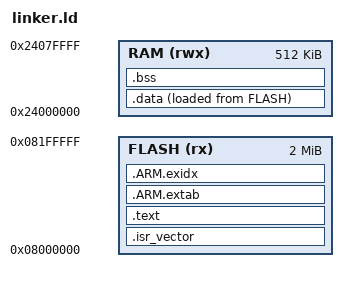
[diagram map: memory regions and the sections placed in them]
ENTRY(Reset_Handler)

MEMORY
{
    FLASH (rx)  : ORIGIN = 0x08000000, LENGTH = 2048K
    RAM   (rwx) : ORIGIN = 0x24000000, LENGTH = 512K
}

__RAM_START__ = ORIGIN(RAM);
__RAM_END__ = ORIGIN(RAM) + LENGTH(RAM);
__StackTop = ORIGIN(RAM) + LENGTH(RAM);

SECTIONS
{
    .isr_vector :
    {
        KEEP(*(.isr_vector))
    } > FLASH

    .text :
    {
        *(.text*)
        *(.rodata*)
        KEEP(*(.init))
        KEEP(*(.fini))
    } > FLASH

    .ARM.extab :
    {
        *(.ARM.extab* .gnu.linkonce.armextab.*)
    } > FLASH

    __exidx_start = .;
    .ARM.exidx :
    {
        *(.ARM.exidx* .gnu.linkonce.armexidx.*)
    } > FLASH
    __exidx_end = .;

    .data :
    {
        __data_start__ = .;
        *(.data*)
        __data_end__ = .;
    } > RAM AT > FLASH

    .bss (NOLOAD) :
    {
        __bss_start__ = .;
        *(.bss*)
        *(COMMON)
        __bss_end__ = .;
    } > RAM

    . = ALIGN(8);
    __end__ = .;

    /DISCARD/ :
    {
        *(.comment)
        *(.note*)
    }
}
